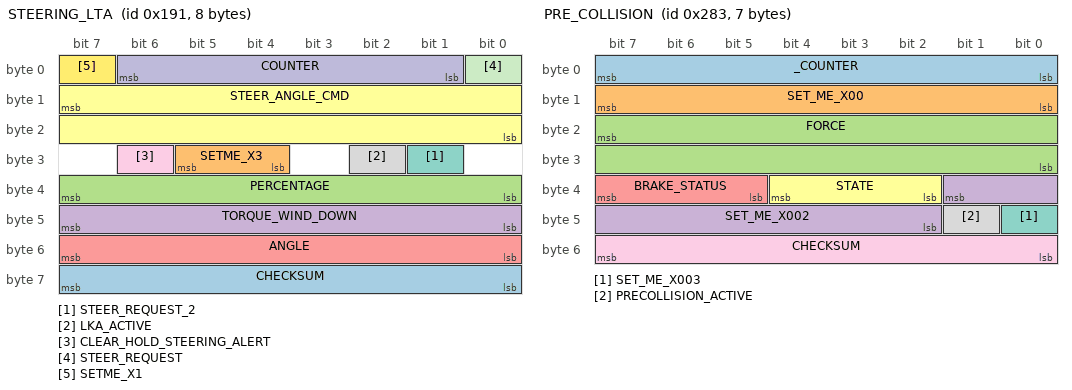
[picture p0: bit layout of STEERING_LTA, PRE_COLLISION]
BO_ 401 STEERING_LTA: 8 XXX
 SG_ CHECKSUM : 63|8@0+ (1,0) [0|255] "" XXX
 SG_ SETME_X3 : 29|2@0+ (1,0) [0|3] "" XXX
 SG_ PERCENTAGE : 39|8@0+ (1,0) [0|255] "" XXX
 SG_ TORQUE_WIND_DOWN : 47|8@0+ (1,0) [0|255] "" XXX
 SG_ ANGLE : 55|8@0- (0.5,0) [0|255] "" XXX
 SG_ STEER_ANGLE_CMD : 15|16@0- (0.0573,0) [-540|540] "" XXX
 SG_ STEER_REQUEST_2 : 25|1@0+ (1,0) [0|1] "" XXX
 SG_ LKA_ACTIVE : 26|1@0+ (1,0) [0|1] "" XXX
 SG_ CLEAR_HOLD_STEERING_ALERT : 30|1@0+ (1,0) [0|1] "" XXX
 SG_ COUNTER : 6|6@0+ (1,0) [0|255] "" XXX
 SG_ STEER_REQUEST : 0|1@0+ (1,0) [0|1] "" XXX
 SG_ SETME_X1 : 7|1@0+ (1,0) [0|1] "" XXX

BO_ 643 PRE_COLLISION: 7 DSU
 SG_ _COUNTER : 7|8@0+ (1,0) [0|255] "" XXX
 SG_ SET_ME_X00 : 15|8@0+ (1,0) [0|255] "" XXX
 SG_ FORCE : 23|16@0- (2,0) [0|255] "N" XXX
 SG_ SET_ME_X002 : 33|8@0+ (1,0) [0|3] "" XXX
 SG_ BRAKE_STATUS : 39|3@0+ (1,0) [0|255] "" XXX
 SG_ STATE : 36|3@0+ (1,0) [0|255] "" XXX
 SG_ SET_ME_X003 : 40|1@0+ (1,0) [0|1] "" XXX
 SG_ PRECOLLISION_ACTIVE : 41|1@0+ (1,0) [0|255] "" XXX
 SG_ CHECKSUM : 55|8@0+ (1,0) [0|255] "" XXX

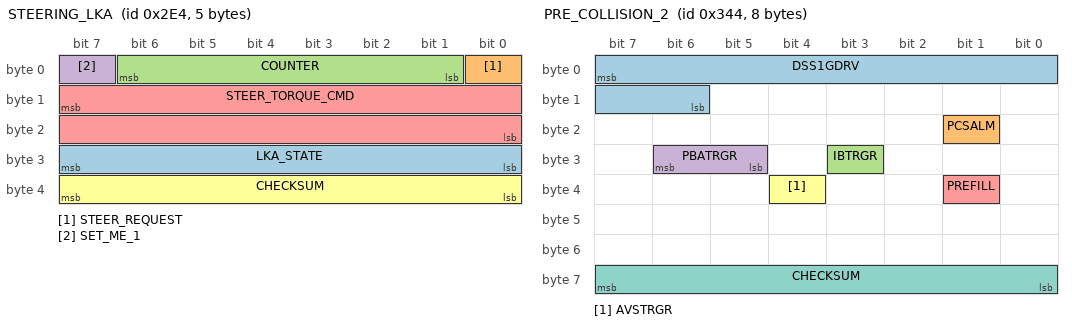
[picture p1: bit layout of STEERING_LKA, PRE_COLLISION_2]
BO_ 740 STEERING_LKA: 5 XXX
 SG_ LKA_STATE : 31|8@0+ (1,0) [0|255] "" XXX
 SG_ STEER_REQUEST : 0|1@0+ (1,0) [0|1] "" XXX
 SG_ COUNTER : 6|6@0+ (1,0) [0|63] "" XXX
 SG_ SET_ME_1 : 7|1@0+ (1,0) [0|1] "" XXX
 SG_ STEER_TORQUE_CMD : 15|16@0- (1,0) [0|65535] "" XXX
 SG_ CHECKSUM : 39|8@0+ (1,0) [0|255] "" XXX

BO_ 836 PRE_COLLISION_2: 8 DSU
 SG_ DSS1GDRV : 7|10@0- (0.1,0) [0|0] "m/s^2" Vector__XXX
 SG_ PCSALM : 17|1@0+ (1,0) [0|0] "" FCM
 SG_ IBTRGR : 27|1@0+ (1,0) [0|0] "" FCM
 SG_ PBATRGR : 30|2@0+ (1,0) [0|0] "" Vector__XXX
 SG_ PREFILL : 33|1@0+ (1,0) [0|0] "" Vector__XXX
 SG_ AVSTRGR : 36|1@0+ (1,0) [0|0] "" SCS
 SG_ CHECKSUM : 63|8@0+ (1,0) [0|0] "" XXX

CM_ SG_ 401 PERCENTAGE "driver override percentage (0-100), very close to steeringPressed in OP";
CM_ SG_ 401 TORQUE_WIND_DOWN "used to wind down torque on user override";
CM_ SG_ 401 ANGLE "angle of car relative to lane center on LTA camera";
CM_ SG_ 401 STEER_ANGLE_CMD "desired angle, OEM steers up to 95 degrees, no angle limit but torque will bottom out";
CM_ SG_ 401 CLEAR_HOLD_STEERING_ALERT "set to 1 when user clears LKAS_HUD->LDA_ALERT ('Hold Steering') by applying torque to steering wheel";
CM_ SG_ 401 STEER_REQUEST "enable bit for steering, 1 to steer, 0 to not";
CM_ SG_ 401 STEER_REQUEST_2 "enable bit for steering, 1 to steer, 0 to not";
CM_ SG_ 401 LKA_ACTIVE "1 when using LTA for LKA";
CM_ SG_ 401 SETME_X1 "usually 1, seen at 0 on some South American Corollas indicating lack of stock Lane Tracing Assist";
CM_ SG_ 401 SETME_X3 "almost completely correlates with Toyota Safety Sense version, but may instead describe max torque when using LTA. if TSS 2.5 or 2022 RAV4, this is always 1. if TSS 2.0 this is always 3 (or 0 on Alphard, Highlander, NX)";
CM_ SG_ 643 _COUNTER "only used on cars that use this msg for cruise control";
CM_ SG_ 643 BRAKE_STATUS "only used on cars that use this msg for cruise control";
CM_ SG_ 643 PRECOLLISION_ACTIVE "set 0.5s before any braking";

VAL_ 401 SETME_X3 3 "TSS 2.0" 1 "TSS 2.5 or 2022 RAV4" 0 "TSS 2.0 on Alphard, Highlander, NX";
VAL_ 643 STATE 0 "normal" 1 "adaptive_cruise_control" 3 "emergency_braking";
